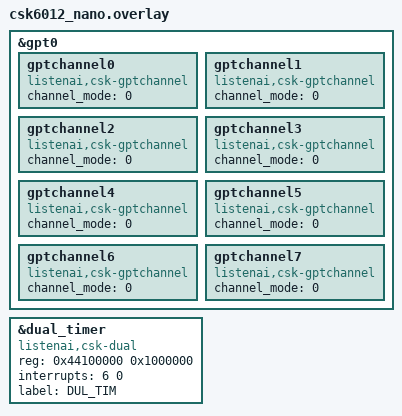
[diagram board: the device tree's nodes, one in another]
&gpt0 {
    gptchannel0:gptchannel0 {
        compatible = "listenai,csk-gptchannel";
        status = "okay";
        channel_mode = <0>;  /* Deprecated */
    };

    gptchannel1:gptchannel1 {
        compatible = "listenai,csk-gptchannel";
        status = "okay";
        channel_mode = <0>;  /* Deprecated */
    };

    gptchannel2:gptchannel2 {
        compatible = "listenai,csk-gptchannel";
        status = "okay";
        channel_mode = <0>;  /* Deprecated */
    };

    gptchannel3:gptchannel3 {
        compatible = "listenai,csk-gptchannel";
        status = "okay";
        channel_mode = <0>;  /* Deprecated */
    };

    gptchannel4:gptchannel4 {
        compatible = "listenai,csk-gptchannel";
        status = "okay";
        channel_mode = <0>;  /* Deprecated */
    };

    gptchannel5:gptchannel5 {
        compatible = "listenai,csk-gptchannel";
        status = "okay";
        channel_mode = <0>;  /* Deprecated */
    };

    gptchannel6:gptchannel6 {
        compatible = "listenai,csk-gptchannel";
        status = "okay";
        channel_mode = <0>;  /* Deprecated */
    };
    
    gptchannel7:gptchannel7 {
        compatible = "listenai,csk-gptchannel";
        status = "okay";
        channel_mode = <0>;  /* Deprecated */
    };

};

&dual_timer{
    compatible = "listenai,csk-dual";
    reg = <0x44100000 0x1000000>;
    interrupts = <6 0>;
    label = "DUL_TIM";
};
